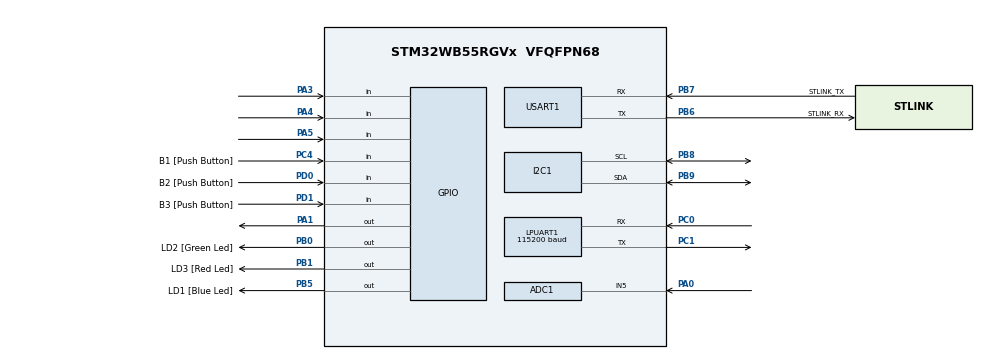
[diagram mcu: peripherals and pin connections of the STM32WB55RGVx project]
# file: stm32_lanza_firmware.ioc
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ADC1.Channel-0\#ChannelRegularConversion=ADC_CHANNEL_5
ADC1.NbrOfConversionFlag=1
ADC1.OffsetNumber-0\#ChannelRegularConversion=ADC_OFFSET_NONE
ADC1.Rank-0\#ChannelRegularConversion=1
ADC1.SamplingTime-0\#ChannelRegularConversion=ADC_SAMPLETIME_47CYCLES_5
ADC1.master=1
I2C1.Timing=0x00B07CB4
LPUART1.BaudRate=115200
Mcu.Family=STM32WB
Mcu.Name=STM32WB55RGVx
Mcu.Package=VFQFPN68
NVIC.PriorityGroup=NVIC_PRIORITYGROUP_4
OSC_IN.GPIO_Label=RCC_OSC_IN
OSC_IN.Mode=HSE-External-Oscillator
OSC_IN.Signal=RCC_OSC_IN
OSC_OUT.GPIO_Label=RCC_OSC_OUT
OSC_OUT.Mode=HSE-External-Oscillator
OSC_OUT.Signal=RCC_OSC_OUT
PA0.Signal=ADCx_IN5
PA1.GPIO_ModeDefaultOutputPP=GPIO_MODE_OUTPUT_OD
PA1.GPIO_PuPd=GPIO_NOPULL
PA1.Signal=GPIO_Output
PA3.Signal=GPIO_Input
PA4.Signal=GPIO_Input
PA5.Signal=GPIO_Input
PB0.GPIO_Label=LD2 [Green Led]
PB0.Signal=GPIO_Output
PB1.GPIO_Label=LD3 [Red Led]
PB1.Signal=GPIO_Output
PB5.GPIO_Label=LD1 [Blue Led]
PB5.Signal=GPIO_Output
PB6.GPIO_Label=STLINK_RX
PB6.Mode=Asynchronous
PB6.Signal=USART1_TX
PB7.GPIO_Label=STLINK_TX
PB7.Mode=Asynchronous
PB7.Signal=USART1_RX
PB8.GPIO_Pu=GPIO_PULLUP
PB8.Mode=I2C
PB8.Signal=I2C1_SCL
PB9.GPIO_Pu=GPIO_PULLUP
PB9.Mode=I2C
PB9.Signal=I2C1_SDA
PC0.Mode=Asynchronous
PC0.Signal=LPUART1_RX
PC1.Mode=Asynchronous
PC1.Signal=LPUART1_TX
PC14-OSC32_IN.Mode=LSE-External-Oscillator
PC14-OSC32_IN.Signal=RCC_OSC32_IN
PC15-OSC32_OUT.Mode=LSE-External-Oscillator
PC15-OSC32_OUT.Signal=RCC_OSC32_OUT
PC4.GPIO_Label=B1 [Push Button]
PC4.Signal=GPIO_Input
PD0.GPIO_Label=B2 [Push Button]
PD0.Signal=GPIO_Input
PD1.GPIO_Label=B3 [Push Button]
PD1.Signal=GPIO_Input
ProjectManager.HeapSize=0x200
ProjectManager.StackSize=0x400
ProjectManager.TargetToolchain=STM32CubeIDE
RCC.ADCFreq_Value=64000000
RCC.AHBFreq_Value=32000000
RCC.APB1Freq_Value=32000000
RCC.APB1TimFreq_Value=32000000
RCC.APB2Freq_Value=32000000
RCC.APB2TimFreq_Value=32000000
RCC.APB3Freq_Value=16000000
RCC.CortexFreq_Value=32000000
RCC.HCLKFreq_Value=32000000
RCC.HSE_VALUE=32000000
RCC.HSI48_VALUE=48000000
RCC.HSI_VALUE=16000000
RCC.MSIClockRange=RCC_MSIRANGE_10
RCC.PLLM=RCC_PLLM_DIV2
RCC.RTCClockSelection=RCC_RTCCLKSOURCE_LSE
RCC.SMPSCLockSelection=RCC_SMPSCLKSOURCE_HSI
RCC.SMPSCLockSelectionVirtual=RCC_SMPSCLKSOURCE_HSI
RCC.SMPSCLockSelectionVirtualVirtual=RCC_SMPSCLKSOURCE_HSI
RCC.SMPSDivider=1
RCC.SYSCLKFreq_VALUE=32000000
RCC.USBFreq_Value=64000000
RCC.VCOOutputFreq_Value=128000000
SH.ADCx_IN5.0=ADC1_IN5,IN5-Single-Ended
USART1.AutoBaudRateEnableParam=UART_ADVFEATURE_AUTOBAUDRATE_DISABLE
USART1.VirtualMode-Asynchronous=VM_ASYNC
VP_MEMORYMAP_VS_MEMORYMAP.Mode=CurAppReg
VP_RTC_VS_RTC_Activate.Mode=RTC_Enabled
VP_RTC_VS_RTC_Calendar.Mode=RTC_Calendar
board=NUCLEO-WB55RG

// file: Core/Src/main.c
/* USER CODE BEGIN Header */
/**
  ******************************************************************************
  * @file           : main.c
  * @brief          : Main program body
  ******************************************************************************
  * @attention
  *
  * Copyright (c) 2025 STMicroelectronics.
  * All rights reserved.
  *
  * This software is licensed under terms that can be found in the LICENSE file
  * in the root directory of this software component.
  * If no LICENSE file comes with this software, it is provided AS-IS.
  *
  ******************************************************************************
  */
/* USER CODE END Header */
#include "main.h"

/* USER CODE BEGIN Includes */
#include "app.h"
/* USER CODE END Includes */

ADC_HandleTypeDef hadc1;

I2C_HandleTypeDef hi2c1;

UART_HandleTypeDef hlpuart1;
UART_HandleTypeDef huart1;

RTC_HandleTypeDef hrtc;

void SystemClock_Config(void);
void PeriphCommonClock_Config(void);
static void MX_GPIO_Init(void);
static void MX_I2C1_Init(void);
static void MX_USART1_UART_Init(void);
static void MX_LPUART1_UART_Init(void);
static void MX_RTC_Init(void);
static void MX_ADC1_Init(void);

/* USER CODE BEGIN 0 */

// Overwritten function to allow printf() via UART
int _write(int file, char *ptr, int len) {
    HAL_UART_Transmit(&huart1, (uint8_t*)ptr, len, HAL_MAX_DELAY);
    return len;
}
/* USER CODE END 0 */

int main(void)
{

  /* MCU Configuration--------------------------------------------------------*/

  /* Reset of all peripherals, Initializes the Flash interface and the Systick. */
  HAL_Init();

  /* Configure the system clock */
  SystemClock_Config();

  /* Configure the peripherals common clocks */
  PeriphCommonClock_Config();

  /* Initialize all configured peripherals */
  MX_GPIO_Init();
  MX_I2C1_Init();
  MX_USART1_UART_Init();
  MX_LPUART1_UART_Init();
  MX_RTC_Init();
  MX_ADC1_Init();
  /* USER CODE BEGIN 2 */
  setup();
  /* USER CODE END 2 */

  /* Infinite loop */
  while (1)
  {

    /* USER CODE BEGIN 3 */
	  loop();
  }
  /* USER CODE END 3 */
}

void SystemClock_Config(void)
{
  RCC_OscInitTypeDef RCC_OscInitStruct = {0};
  RCC_ClkInitTypeDef RCC_ClkInitStruct = {0};

  /** Macro to configure the PLL multiplication factor
  */
  __HAL_RCC_PLL_PLLM_CONFIG(RCC_PLLM_DIV2);

  /** Macro to configure the PLL clock source
  */
  __HAL_RCC_PLL_PLLSOURCE_CONFIG(RCC_PLLSOURCE_MSI);

  /** Configure LSE Drive Capability
  */
  HAL_PWR_EnableBkUpAccess();
  __HAL_RCC_LSEDRIVE_CONFIG(RCC_LSEDRIVE_MEDIUMHIGH);

  /** Configure the main internal regulator output voltage
  */
  __HAL_PWR_VOLTAGESCALING_CONFIG(PWR_REGULATOR_VOLTAGE_SCALE1);

  /** Initializes the RCC Oscillators according to the specified parameters
  * in the RCC_OscInitTypeDef structure.
  */
  RCC_OscInitStruct.OscillatorType = RCC_OSCILLATORTYPE_HSI|RCC_OSCILLATORTYPE_HSE
                              |RCC_OSCILLATORTYPE_LSE|RCC_OSCILLATORTYPE_MSI;
  RCC_OscInitStruct.HSEState = RCC_HSE_ON;
  RCC_OscInitStruct.LSEState = RCC_LSE_ON;
  RCC_OscInitStruct.HSIState = RCC_HSI_ON;
  RCC_OscInitStruct.MSIState = RCC_MSI_ON;
  RCC_OscInitStruct.HSICalibrationValue = RCC_HSICALIBRATION_DEFAULT;
  RCC_OscInitStruct.MSICalibrationValue = RCC_MSICALIBRATION_DEFAULT;
  RCC_OscInitStruct.MSIClockRange = RCC_MSIRANGE_10;
  RCC_OscInitStruct.PLL.PLLState = RCC_PLL_NONE;
  if (HAL_RCC_OscConfig(&RCC_OscInitStruct) != HAL_OK)
  {
    Error_Handler();
  }

  /** Configure the SYSCLKSource, HCLK, PCLK1 and PCLK2 clocks dividers
  */
  RCC_ClkInitStruct.ClockType = RCC_CLOCKTYPE_HCLK4|RCC_CLOCKTYPE_HCLK2
                              |RCC_CLOCKTYPE_HCLK|RCC_CLOCKTYPE_SYSCLK
                              |RCC_CLOCKTYPE_PCLK1|RCC_CLOCKTYPE_PCLK2;
  RCC_ClkInitStruct.SYSCLKSource = RCC_SYSCLKSOURCE_MSI;
  RCC_ClkInitStruct.AHBCLKDivider = RCC_SYSCLK_DIV1;
  RCC_ClkInitStruct.APB1CLKDivider = RCC_HCLK_DIV1;
  RCC_ClkInitStruct.APB2CLKDivider = RCC_HCLK_DIV1;
  RCC_ClkInitStruct.AHBCLK2Divider = RCC_SYSCLK_DIV1;
  RCC_ClkInitStruct.AHBCLK4Divider = RCC_SYSCLK_DIV1;

  if (HAL_RCC_ClockConfig(&RCC_ClkInitStruct, FLASH_LATENCY_1) != HAL_OK)
  {
    Error_Handler();
  }
}

void PeriphCommonClock_Config(void)
{
  RCC_PeriphCLKInitTypeDef PeriphClkInitStruct = {0};

  /** Initializes the peripherals clock
  */
  PeriphClkInitStruct.PeriphClockSelection = RCC_PERIPHCLK_SMPS;
  PeriphClkInitStruct.SmpsClockSelection = RCC_SMPSCLKSOURCE_HSI;
  PeriphClkInitStruct.SmpsDivSelection = RCC_SMPSCLKDIV_RANGE0;

  if (HAL_RCCEx_PeriphCLKConfig(&PeriphClkInitStruct) != HAL_OK)
  {
    Error_Handler();
  }
}

static void MX_ADC1_Init(void)
{

  ADC_ChannelConfTypeDef sConfig = {0};

  /** Common config
  */
  hadc1.Instance = ADC1;
  hadc1.Init.ClockPrescaler = ADC_CLOCK_ASYNC_DIV1;
  hadc1.Init.Resolution = ADC_RESOLUTION_12B;
  hadc1.Init.DataAlign = ADC_DATAALIGN_RIGHT;
  hadc1.Init.ScanConvMode = ADC_SCAN_DISABLE;
  hadc1.Init.EOCSelection = ADC_EOC_SINGLE_CONV;
  hadc1.Init.LowPowerAutoWait = DISABLE;
  hadc1.Init.ContinuousConvMode = DISABLE;
  hadc1.Init.NbrOfConversion = 1;
  hadc1.Init.DiscontinuousConvMode = DISABLE;
  hadc1.Init.ExternalTrigConv = ADC_SOFTWARE_START;
  hadc1.Init.ExternalTrigConvEdge = ADC_EXTERNALTRIGCONVEDGE_NONE;
  hadc1.Init.DMAContinuousRequests = DISABLE;
  hadc1.Init.Overrun = ADC_OVR_DATA_PRESERVED;
  hadc1.Init.OversamplingMode = DISABLE;
  if (HAL_ADC_Init(&hadc1) != HAL_OK)
  {
    Error_Handler();
  }

  /** Configure Regular Channel
  */
  sConfig.Channel = ADC_CHANNEL_5;
  sConfig.Rank = ADC_REGULAR_RANK_1;
  sConfig.SamplingTime = ADC_SAMPLETIME_47CYCLES_5;
  sConfig.SingleDiff = ADC_SINGLE_ENDED;
  sConfig.OffsetNumber = ADC_OFFSET_NONE;
  sConfig.Offset = 0;
  if (HAL_ADC_ConfigChannel(&hadc1, &sConfig) != HAL_OK)
  {
    Error_Handler();
  }

}

static void MX_I2C1_Init(void)
{

  hi2c1.Instance = I2C1;
  hi2c1.Init.Timing = 0x00B07CB4;
  hi2c1.Init.OwnAddress1 = 0;
  hi2c1.Init.AddressingMode = I2C_ADDRESSINGMODE_7BIT;
  hi2c1.Init.DualAddressMode = I2C_DUALADDRESS_DISABLE;
  hi2c1.Init.OwnAddress2 = 0;
  hi2c1.Init.OwnAddress2Masks = I2C_OA2_NOMASK;
  hi2c1.Init.GeneralCallMode = I2C_GENERALCALL_DISABLE;
  hi2c1.Init.NoStretchMode = I2C_NOSTRETCH_DISABLE;
  if (HAL_I2C_Init(&hi2c1) != HAL_OK)
  {
    Error_Handler();
  }

  /** Configure Analogue filter
  */
  if (HAL_I2CEx_ConfigAnalogFilter(&hi2c1, I2C_ANALOGFILTER_ENABLE) != HAL_OK)
  {
    Error_Handler();
  }

  /** Configure Digital filter
  */
  if (HAL_I2CEx_ConfigDigitalFilter(&hi2c1, 0) != HAL_OK)
  {
    Error_Handler();
  }

}

static void MX_LPUART1_UART_Init(void)
{

  hlpuart1.Instance = LPUART1;
  hlpuart1.Init.BaudRate = 115200;
  hlpuart1.Init.WordLength = UART_WORDLENGTH_8B;
  hlpuart1.Init.StopBits = UART_STOPBITS_1;
  hlpuart1.Init.Parity = UART_PARITY_NONE;
  hlpuart1.Init.Mode = UART_MODE_TX_RX;
  hlpuart1.Init.HwFlowCtl = UART_HWCONTROL_NONE;
  hlpuart1.Init.OneBitSampling = UART_ONE_BIT_SAMPLE_DISABLE;
  hlpuart1.Init.ClockPrescaler = UART_PRESCALER_DIV1;
  hlpuart1.AdvancedInit.AdvFeatureInit = UART_ADVFEATURE_NO_INIT;
  hlpuart1.FifoMode = UART_FIFOMODE_DISABLE;
  if (HAL_UART_Init(&hlpuart1) != HAL_OK)
  {
    Error_Handler();
  }
  if (HAL_UARTEx_SetTxFifoThreshold(&hlpuart1, UART_TXFIFO_THRESHOLD_1_8) != HAL_OK)
  {
    Error_Handler();
  }
  if (HAL_UARTEx_SetRxFifoThreshold(&hlpuart1, UART_RXFIFO_THRESHOLD_1_8) != HAL_OK)
  {
    Error_Handler();
  }
  if (HAL_UARTEx_DisableFifoMode(&hlpuart1) != HAL_OK)
  {
    Error_Handler();
  }

}

static void MX_USART1_UART_Init(void)
{

  huart1.Instance = USART1;
  huart1.Init.BaudRate = 115200;
  huart1.Init.WordLength = UART_WORDLENGTH_8B;
  huart1.Init.StopBits = UART_STOPBITS_1;
  huart1.Init.Parity = UART_PARITY_NONE;
  huart1.Init.Mode = UART_MODE_TX_RX;
  huart1.Init.HwFlowCtl = UART_HWCONTROL_NONE;
  huart1.Init.OverSampling = UART_OVERSAMPLING_16;
  huart1.Init.OneBitSampling = UART_ONE_BIT_SAMPLE_DISABLE;
  huart1.Init.ClockPrescaler = UART_PRESCALER_DIV1;
  huart1.AdvancedInit.AdvFeatureInit = UART_ADVFEATURE_NO_INIT;
  if (HAL_UART_Init(&huart1) != HAL_OK)
  {
    Error_Handler();
  }
  if (HAL_UARTEx_SetTxFifoThreshold(&huart1, UART_TXFIFO_THRESHOLD_1_8) != HAL_OK)
  {
    Error_Handler();
  }
  if (HAL_UARTEx_SetRxFifoThreshold(&huart1, UART_RXFIFO_THRESHOLD_1_8) != HAL_OK)
  {
    Error_Handler();
  }
  if (HAL_UARTEx_DisableFifoMode(&huart1) != HAL_OK)
  {
    Error_Handler();
  }

}

static void MX_RTC_Init(void)
{

  RTC_TimeTypeDef sTime = {0};
  RTC_DateTypeDef sDate = {0};

  /** Initialize RTC Only
  */
  hrtc.Instance = RTC;
  hrtc.Init.HourFormat = RTC_HOURFORMAT_24;
  hrtc.Init.AsynchPrediv = 127;
  hrtc.Init.SynchPrediv = 255;
  hrtc.Init.OutPut = RTC_OUTPUT_DISABLE;
  hrtc.Init.OutPutPolarity = RTC_OUTPUT_POLARITY_HIGH;
  hrtc.Init.OutPutType = RTC_OUTPUT_TYPE_OPENDRAIN;
  hrtc.Init.OutPutRemap = RTC_OUTPUT_REMAP_NONE;
  if (HAL_RTC_Init(&hrtc) != HAL_OK)
  {
    Error_Handler();
  }

  /** Initialize RTC and set the Time and Date
  */
  sTime.Hours = 0x0;
  sTime.Minutes = 0x0;
  sTime.Seconds = 0x0;
  sTime.SubSeconds = 0x0;
  sTime.DayLightSaving = RTC_DAYLIGHTSAVING_NONE;
  sTime.StoreOperation = RTC_STOREOPERATION_RESET;
  if (HAL_RTC_SetTime(&hrtc, &sTime, RTC_FORMAT_BCD) != HAL_OK)
  {
    Error_Handler();
  }
  sDate.WeekDay = RTC_WEEKDAY_MONDAY;
  sDate.Month = RTC_MONTH_JANUARY;
  sDate.Date = 0x1;
  sDate.Year = 0x0;

  if (HAL_RTC_SetDate(&hrtc, &sDate, RTC_FORMAT_BCD) != HAL_OK)
  {
    Error_Handler();
  }

}

static void MX_GPIO_Init(void)
{
  GPIO_InitTypeDef GPIO_InitStruct = {0};

  /* GPIO Ports Clock Enable */
  __HAL_RCC_GPIOC_CLK_ENABLE();
  __HAL_RCC_GPIOB_CLK_ENABLE();
  __HAL_RCC_GPIOA_CLK_ENABLE();
  __HAL_RCC_GPIOD_CLK_ENABLE();

  /*Configure GPIO pin Output Level */
  HAL_GPIO_WritePin(GPIOB, LD2_Pin|LD3_Pin|LD1_Pin, GPIO_PIN_RESET);

  /*Configure GPIO pins : PA3 PA4 PA5 */
  GPIO_InitStruct.Pin = GPIO_PIN_3|GPIO_PIN_4|GPIO_PIN_5;
  GPIO_InitStruct.Mode = GPIO_MODE_INPUT;
  GPIO_InitStruct.Pull = GPIO_NOPULL;
  HAL_GPIO_Init(GPIOA, &GPIO_InitStruct);

  /*Configure GPIO pin : B1_Pin */
  GPIO_InitStruct.Pin = B1_Pin;
  GPIO_InitStruct.Mode = GPIO_MODE_INPUT;
  GPIO_InitStruct.Pull = GPIO_NOPULL;
  HAL_GPIO_Init(B1_GPIO_Port, &GPIO_InitStruct);

  /*Configure GPIO pins : LD2_Pin LD3_Pin LD1_Pin */
  GPIO_InitStruct.Pin = LD2_Pin|LD3_Pin|LD1_Pin;
  GPIO_InitStruct.Mode = GPIO_MODE_OUTPUT_PP;
  GPIO_InitStruct.Pull = GPIO_NOPULL;
  GPIO_InitStruct.Speed = GPIO_SPEED_FREQ_LOW;
  HAL_GPIO_Init(GPIOB, &GPIO_InitStruct);

  /*Configure GPIO pins : B2_Pin B3_Pin */
  GPIO_InitStruct.Pin = B2_Pin|B3_Pin;
  GPIO_InitStruct.Mode = GPIO_MODE_INPUT;
  GPIO_InitStruct.Pull = GPIO_NOPULL;
  HAL_GPIO_Init(GPIOD, &GPIO_InitStruct);

}

void Error_Handler(void)
{
  __disable_irq();
  while (1)
  {
  }
}
